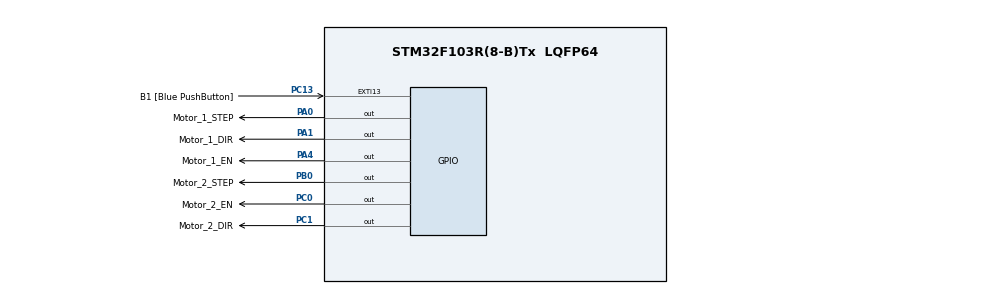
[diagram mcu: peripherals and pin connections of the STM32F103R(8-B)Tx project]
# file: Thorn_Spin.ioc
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Mcu.Family=STM32F1
Mcu.Name=STM32F103R(8-B)Tx
Mcu.Package=LQFP64
NVIC.EXTI15_10_IRQn=true\:0\:0\:false\:false\:true\:true\:true\:true
NVIC.PriorityGroup=NVIC_PRIORITYGROUP_4
NVIC.TIM2_IRQn=true\:0\:0\:false\:false\:true\:true\:true\:true
PA0-WKUP.GPIO_Label=Motor_1_STEP
PA0-WKUP.GPIO_Speed=GPIO_SPEED_FREQ_HIGH
PA0-WKUP.Signal=GPIO_Output
PA1.GPIO_Label=Motor_1_DIR
PA1.GPIO_Speed=GPIO_SPEED_FREQ_HIGH
PA1.Signal=GPIO_Output
PA13.GPIO_Label=TMS
PA13.Mode=Serial_Wire
PA13.Signal=SYS_JTMS-SWDIO
PA14.GPIO_Label=TCK
PA14.Mode=Serial_Wire
PA14.Signal=SYS_JTCK-SWCLK
PA4.GPIO_Label=Motor_1_EN
PA4.GPIO_Speed=GPIO_SPEED_FREQ_HIGH
PA4.Signal=GPIO_Output
PB0.GPIO_Label=Motor_2_STEP
PB0.GPIO_Speed=GPIO_SPEED_FREQ_HIGH
PB0.Signal=GPIO_Output
PB3.GPIO_Label=SWO
PB3.Signal=SYS_JTDO-TRACESWO
PC0.GPIO_Label=Motor_2_EN
PC0.GPIO_Speed=GPIO_SPEED_FREQ_HIGH
PC0.Signal=GPIO_Output
PC1.GPIO_Label=Motor_2_DIR
PC1.GPIO_Speed=GPIO_SPEED_FREQ_HIGH
PC1.Signal=GPIO_Output
PC13-TAMPER-RTC.GPIO_Label=B1 [Blue PushButton]
PC13-TAMPER-RTC.GPIO_PuPd=GPIO_NOPULL
PC13-TAMPER-RTC.Signal=GPXTI13
PC14-OSC32_IN.Mode=LSE-External-Oscillator
PC14-OSC32_IN.Signal=RCC_OSC32_IN
PC15-OSC32_OUT.Mode=LSE-External-Oscillator
PC15-OSC32_OUT.Signal=RCC_OSC32_OUT
PD0-OSC_IN.Mode=HSE-External-Clock-Source
PD0-OSC_IN.Signal=RCC_OSC_IN
PD1-OSC_OUT.Mode=HSE-External-Clock-Source
PD1-OSC_OUT.Signal=RCC_OSC_OUT
ProjectManager.HeapSize=0x200
ProjectManager.StackSize=0x400
ProjectManager.TargetToolchain=STM32CubeIDE
RCC.AHBFreq_Value=72000000
RCC.APB1CLKDivider=RCC_HCLK_DIV2
RCC.APB1Freq_Value=36000000
RCC.APB1TimFreq_Value=72000000
RCC.APB2Freq_Value=72000000
RCC.APB2TimFreq_Value=72000000
RCC.HCLKFreq_Value=72000000
RCC.PLLMUL=RCC_PLL_MUL9
RCC.PLLSourceVirtual=RCC_PLLSOURCE_HSE
RCC.RTCClockSelection=RCC_RTCCLKSOURCE_LSE
RCC.SYSCLKFreq_VALUE=72000000
RCC.SYSCLKSource=RCC_SYSCLKSOURCE_PLLCLK
RCC.USBFreq_Value=72000000
TIM2.Period=50-1
TIM2.Prescaler=72-1
VP_TIM2_VS_ClockSourceINT.Mode=Internal
board=NUCLEO-F103RB

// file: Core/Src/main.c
/* USER CODE BEGIN Header */
/**
  ******************************************************************************
  * @file           : main.c
  * @brief          : Main program body
  ******************************************************************************
  * @attention
  *
  * Copyright (c) 2026 STMicroelectronics.
  * All rights reserved.
  *
  * This software is licensed under terms that can be found in the LICENSE file
  * in the root directory of this software component.
  * If no LICENSE file comes with this software, it is provided AS-IS.
  *
  ******************************************************************************
  */
/* USER CODE END Header */
#include "main.h"

/* USER CODE BEGIN Includes */
#include "motor_player.h"
/* USER CODE END Includes */

void SystemClock_Config(void);
static void MX_GPIO_Init(void);
static void MX_TIM2_Init(void);

int main(void)
{

  /* MCU Configuration--------------------------------------------------------*/

  /* Reset of all peripherals, Initializes the Flash interface and the Systick. */
  LL_APB2_GRP1_EnableClock(LL_APB2_GRP1_PERIPH_AFIO);
  LL_APB1_GRP1_EnableClock(LL_APB1_GRP1_PERIPH_PWR);

  /* System interrupt init*/
  NVIC_SetPriorityGrouping(NVIC_PRIORITYGROUP_4);

  /** NOJTAG: JTAG-DP Disabled and SW-DP Enabled
  */
  LL_GPIO_AF_Remap_SWJ_NOJTAG();

  /* Configure the system clock */
  SystemClock_Config();

  /* Initialize all configured peripherals */
  MX_GPIO_Init();
  MX_TIM2_Init();
  /* USER CODE BEGIN 2 */
  MotorPlayer_Init();
  /* USER CODE END 2 */

  /* Infinite loop */
  /* USER CODE BEGIN WHILE */
  while (1)
  {
    MotorPlayer_Play();
    LL_mDelay(1000);
    /* USER CODE END WHILE */

  }
}

void SystemClock_Config(void)
{
  LL_FLASH_SetLatency(LL_FLASH_LATENCY_2);
  while(LL_FLASH_GetLatency()!= LL_FLASH_LATENCY_2)
  {
  }
  LL_RCC_HSE_EnableBypass();
  LL_RCC_HSE_Enable();

   /* Wait till HSE is ready */
  while(LL_RCC_HSE_IsReady() != 1)
  {

  }
  LL_RCC_PLL_ConfigDomain_SYS(LL_RCC_PLLSOURCE_HSE_DIV_1, LL_RCC_PLL_MUL_9);
  LL_RCC_PLL_Enable();

   /* Wait till PLL is ready */
  while(LL_RCC_PLL_IsReady() != 1)
  {

  }
  LL_RCC_SetAHBPrescaler(LL_RCC_SYSCLK_DIV_1);
  LL_RCC_SetAPB1Prescaler(LL_RCC_APB1_DIV_2);
  LL_RCC_SetAPB2Prescaler(LL_RCC_APB2_DIV_1);
  LL_RCC_SetSysClkSource(LL_RCC_SYS_CLKSOURCE_PLL);

   /* Wait till System clock is ready */
  while(LL_RCC_GetSysClkSource() != LL_RCC_SYS_CLKSOURCE_STATUS_PLL)
  {

  }
  LL_Init1msTick(72000000);
  LL_SetSystemCoreClock(72000000);
}

static void MX_TIM2_Init(void)
{

  LL_TIM_InitTypeDef TIM_InitStruct = {0};

  /* Peripheral clock enable */
  LL_APB1_GRP1_EnableClock(LL_APB1_GRP1_PERIPH_TIM2);

  /* TIM2 interrupt Init */
  NVIC_SetPriority(TIM2_IRQn, NVIC_EncodePriority(NVIC_GetPriorityGrouping(),0, 0));
  NVIC_EnableIRQ(TIM2_IRQn);

  TIM_InitStruct.Prescaler = 72-1;
  TIM_InitStruct.CounterMode = LL_TIM_COUNTERMODE_UP;
  TIM_InitStruct.Autoreload = 50-1;
  TIM_InitStruct.ClockDivision = LL_TIM_CLOCKDIVISION_DIV1;
  LL_TIM_Init(TIM2, &TIM_InitStruct);
  LL_TIM_DisableARRPreload(TIM2);
  LL_TIM_SetClockSource(TIM2, LL_TIM_CLOCKSOURCE_INTERNAL);
  LL_TIM_SetTriggerOutput(TIM2, LL_TIM_TRGO_RESET);
  LL_TIM_DisableMasterSlaveMode(TIM2);

}

static void MX_GPIO_Init(void)
{
  LL_EXTI_InitTypeDef EXTI_InitStruct = {0};
  LL_GPIO_InitTypeDef GPIO_InitStruct = {0};

  /* GPIO Ports Clock Enable */
  LL_APB2_GRP1_EnableClock(LL_APB2_GRP1_PERIPH_GPIOC);
  LL_APB2_GRP1_EnableClock(LL_APB2_GRP1_PERIPH_GPIOD);
  LL_APB2_GRP1_EnableClock(LL_APB2_GRP1_PERIPH_GPIOA);
  LL_APB2_GRP1_EnableClock(LL_APB2_GRP1_PERIPH_GPIOB);

  /**/
  LL_GPIO_ResetOutputPin(GPIOC, Motor_2_EN_Pin|Motor_2_DIR_Pin);

  /**/
  LL_GPIO_ResetOutputPin(GPIOA, Motor_1_STEP_Pin|Motor_1_DIR_Pin|Motor_1_EN_Pin);

  /**/
  LL_GPIO_ResetOutputPin(GPIOB, Motor_2_STEP_Pin);

  /**/
  LL_GPIO_AF_SetEXTISource(LL_GPIO_AF_EXTI_PORTC, LL_GPIO_AF_EXTI_LINE13);

  /**/
  EXTI_InitStruct.Line_0_31 = LL_EXTI_LINE_13;
  EXTI_InitStruct.LineCommand = ENABLE;
  EXTI_InitStruct.Mode = LL_EXTI_MODE_IT;
  EXTI_InitStruct.Trigger = LL_EXTI_TRIGGER_RISING;
  LL_EXTI_Init(&EXTI_InitStruct);

  /**/
  LL_GPIO_SetPinMode(B1_GPIO_Port, B1_Pin, LL_GPIO_MODE_FLOATING);

  /**/
  GPIO_InitStruct.Pin = Motor_2_EN_Pin|Motor_2_DIR_Pin;
  GPIO_InitStruct.Mode = LL_GPIO_MODE_OUTPUT;
  GPIO_InitStruct.Speed = LL_GPIO_SPEED_FREQ_HIGH;
  GPIO_InitStruct.OutputType = LL_GPIO_OUTPUT_PUSHPULL;
  LL_GPIO_Init(GPIOC, &GPIO_InitStruct);

  /**/
  GPIO_InitStruct.Pin = Motor_1_STEP_Pin|Motor_1_DIR_Pin|Motor_1_EN_Pin;
  GPIO_InitStruct.Mode = LL_GPIO_MODE_OUTPUT;
  GPIO_InitStruct.Speed = LL_GPIO_SPEED_FREQ_HIGH;
  GPIO_InitStruct.OutputType = LL_GPIO_OUTPUT_PUSHPULL;
  LL_GPIO_Init(GPIOA, &GPIO_InitStruct);

  /**/
  GPIO_InitStruct.Pin = Motor_2_STEP_Pin;
  GPIO_InitStruct.Mode = LL_GPIO_MODE_OUTPUT;
  GPIO_InitStruct.Speed = LL_GPIO_SPEED_FREQ_HIGH;
  GPIO_InitStruct.OutputType = LL_GPIO_OUTPUT_PUSHPULL;
  LL_GPIO_Init(Motor_2_STEP_GPIO_Port, &GPIO_InitStruct);

  /* EXTI interrupt init*/
  NVIC_SetPriority(EXTI15_10_IRQn, NVIC_EncodePriority(NVIC_GetPriorityGrouping(),0, 0));
  NVIC_EnableIRQ(EXTI15_10_IRQn);

}

void Error_Handler(void)
{
  __disable_irq();
  while (1)
  {
  }
}
